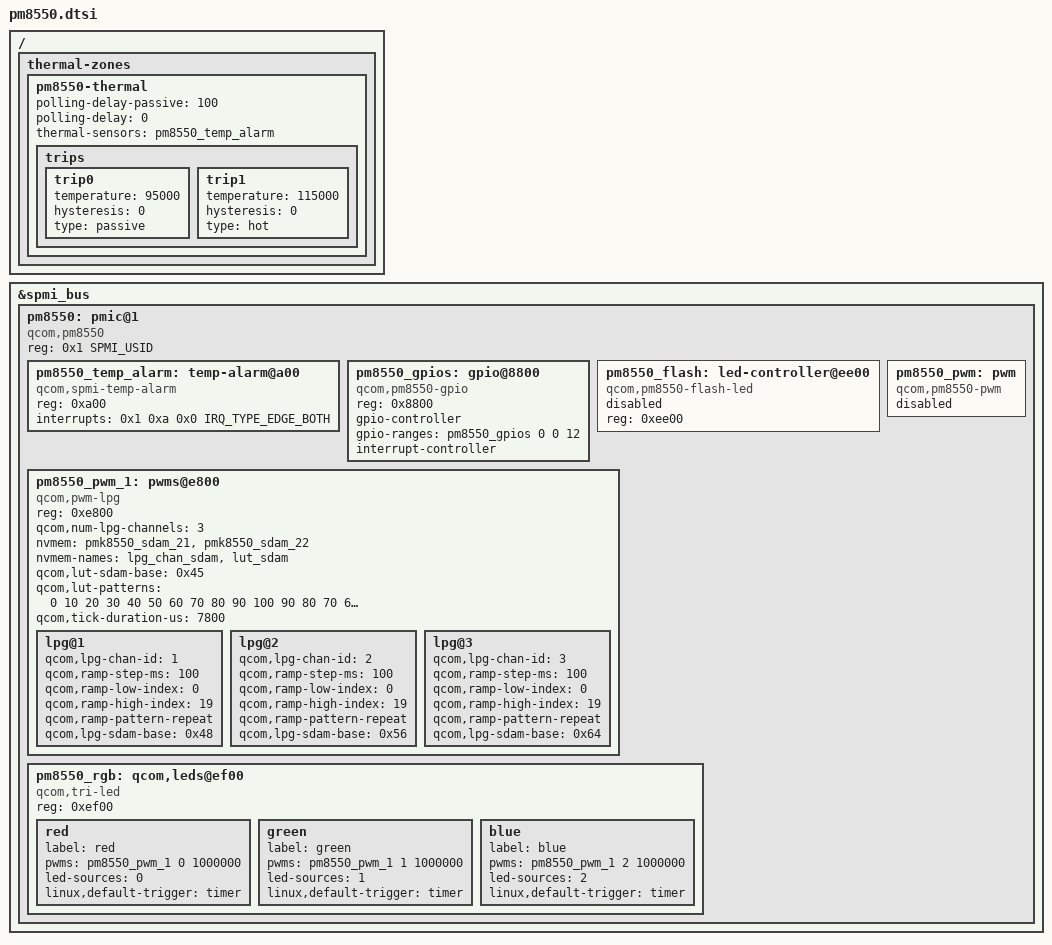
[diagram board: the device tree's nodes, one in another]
// SPDX-License-Identifier: BSD-3-Clause
/*
 * Copyright (c) 2022, Linaro Limited
 */

#include <dt-bindings/interrupt-controller/irq.h>
#include <dt-bindings/spmi/spmi.h>

/ {
	thermal-zones {
		pm8550-thermal {
			polling-delay-passive = <100>;
			polling-delay = <0>;

			thermal-sensors = <&pm8550_temp_alarm>;

			trips {
				trip0 {
					temperature = <95000>;
					hysteresis = <0>;
					type = "passive";
				};

				trip1 {
					temperature = <115000>;
					hysteresis = <0>;
					type = "hot";
				};
			};
		};
	};
};


&spmi_bus {
	pm8550: pmic@1 {
		compatible = "qcom,pm8550", "qcom,spmi-pmic";
		reg = <0x1 SPMI_USID>;
		#address-cells = <1>;
		#size-cells = <0>;

		pm8550_temp_alarm: temp-alarm@a00 {
			compatible = "qcom,spmi-temp-alarm";
			reg = <0xa00>;
			interrupts = <0x1 0xa 0x0 IRQ_TYPE_EDGE_BOTH>;
			#thermal-sensor-cells = <0>;
		};

		pm8550_gpios: gpio@8800 {
			compatible = "qcom,pm8550-gpio", "qcom,spmi-gpio";
			reg = <0x8800>;
			gpio-controller;
			gpio-ranges = <&pm8550_gpios 0 0 12>;
			#gpio-cells = <2>;
			interrupt-controller;
			#interrupt-cells = <2>;
		};

		pm8550_flash: led-controller@ee00 {
			compatible = "qcom,pm8550-flash-led", "qcom,spmi-flash-led";
			reg = <0xee00>;
			status = "disabled";
		};

		pm8550_pwm: pwm {
			compatible = "qcom,pm8550-pwm", "qcom,pm8350c-pwm";
			#pwm-cells = <2>;

			status = "disabled";
		};

		pm8550_pwm_1: pwms@e800 {
			compatible = "qcom,pwm-lpg";
			reg = <0xe800>;
			reg-names = "lpg-base";
			#pwm-cells = <2>;
			qcom,num-lpg-channels = <3>;
			nvmem = <&pmk8550_sdam_21 &pmk8550_sdam_22>;
			nvmem-names = "lpg_chan_sdam", "lut_sdam";
			qcom,lut-sdam-base = <0x45>;
			qcom,lut-patterns = <0 10 20 30 40 50 60 70 80 90 100
					     90 80 70 60 50 40 30 20 10 0>;
			qcom,tick-duration-us = <7800>;

			status = "okay";

			lpg@1 {
				qcom,lpg-chan-id = <1>;
				qcom,ramp-step-ms = <100>;
				qcom,ramp-low-index = <0>;
				qcom,ramp-high-index = <19>;
				qcom,ramp-pattern-repeat;
				qcom,lpg-sdam-base = <0x48>;
			};

			lpg@2 {
				qcom,lpg-chan-id = <2>;
				qcom,ramp-step-ms = <100>;
				qcom,ramp-low-index = <0>;
				qcom,ramp-high-index = <19>;
				qcom,ramp-pattern-repeat;
				qcom,lpg-sdam-base = <0x56>;
			};

			lpg@3 {
				qcom,lpg-chan-id = <3>;
				qcom,ramp-step-ms = <100>;
				qcom,ramp-low-index = <0>;
				qcom,ramp-high-index = <19>;
				qcom,ramp-pattern-repeat;
				qcom,lpg-sdam-base = <0x64>;
			};
		};

		pm8550_rgb: qcom,leds@ef00 {
			compatible = "qcom,tri-led";
			reg = <0xef00>;

			status = "okay";

			red {
				label = "red";
				pwms = <&pm8550_pwm_1 0 1000000>;
				led-sources = <0>;
				linux,default-trigger = "timer";
			};

			green {
				label = "green";
				pwms = <&pm8550_pwm_1 1 1000000>;
				led-sources = <1>;
				linux,default-trigger = "timer";
			};

			blue {
				label = "blue";
				pwms = <&pm8550_pwm_1 2 1000000>;
				led-sources = <2>;
				linux,default-trigger = "timer";
			};
		};
	};
};
